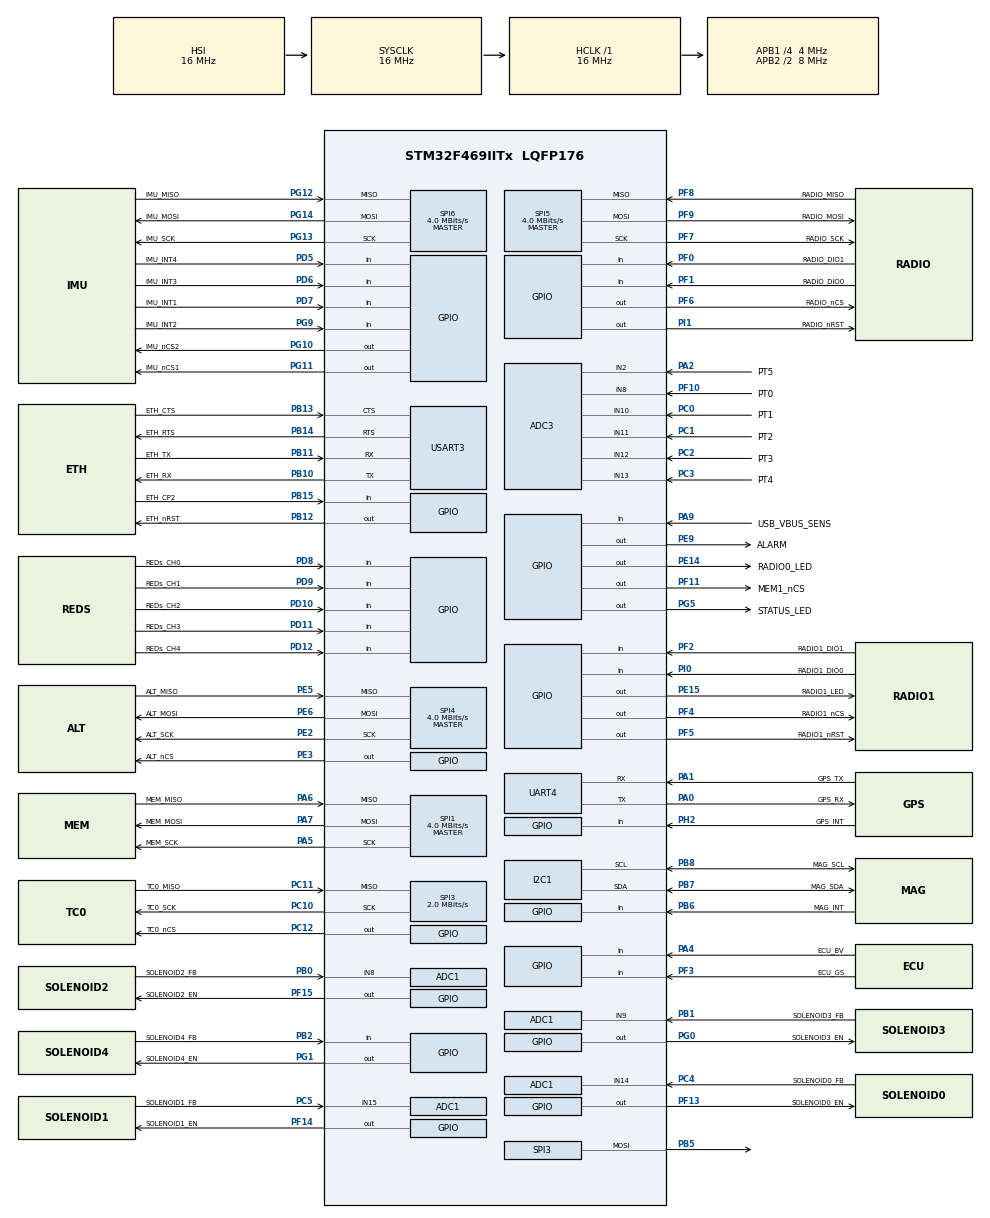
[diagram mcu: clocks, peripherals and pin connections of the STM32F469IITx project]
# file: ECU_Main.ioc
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ADC1.Channel-0\#ChannelRegularConversion=ADC_CHANNEL_8
ADC1.ClockPrescaler=ADC_CLOCK_SYNC_PCLK_DIV4
ADC1.NbrOfConversionFlag=1
ADC1.Rank-0\#ChannelRegularConversion=1
ADC1.SamplingTime-0\#ChannelRegularConversion=ADC_SAMPLETIME_3CYCLES
ADC1.master=1
ADC3.Channel-0\#ChannelRegularConversion=ADC_CHANNEL_10
ADC3.ClockPrescaler=ADC_CLOCK_SYNC_PCLK_DIV4
ADC3.NbrOfConversionFlag=1
ADC3.Rank-0\#ChannelRegularConversion=1
ADC3.SamplingTime-0\#ChannelRegularConversion=ADC_SAMPLETIME_3CYCLES
Mcu.Family=STM32F4
Mcu.Name=STM32F469IITx
Mcu.Package=LQFP176
NVIC.PriorityGroup=NVIC_PRIORITYGROUP_4
PA0/WKUP.GPIO_Label=GPS_RX
PA0/WKUP.Mode=Asynchronous
PA0/WKUP.Signal=UART4_TX
PA1.GPIO_Label=GPS_TX
PA1.Mode=Asynchronous
PA1.Signal=UART4_RX
PA11.GPIO_Label=USB_DM
PA11.Signal=USB_OTG_FS_DM
PA12.GPIO_Label=USB_DP
PA12.Signal=USB_OTG_FS_DP
PA13.Mode=JTAG_4_pins
PA13.Signal=SYS_JTMS-SWDIO
PA14.Mode=JTAG_4_pins
PA14.Signal=SYS_JTCK-SWCLK
PA15.Mode=JTAG_4_pins
PA15.Signal=SYS_JTDI
PA2.GPIO_Label=PT5
PA2.Signal=ADCx_IN2
PA4.GPIO_Label=ECU_BV
PA4.Signal=GPIO_Input
PA5.GPIO_Label=MEM_SCK
PA5.Mode=Full_Duplex_Master
PA5.Signal=SPI1_SCK
PA6.GPIO_Label=MEM_MISO
PA6.Mode=Full_Duplex_Master
PA6.Signal=SPI1_MISO
PA7.GPIO_Label=MEM_MOSI
PA7.Mode=Full_Duplex_Master
PA7.Signal=SPI1_MOSI
PA9.GPIO_Label=USB_VBUS_SENS
PA9.Signal=GPIO_Input
PB0.GPIO_Label=SOLENOID2_FB
PB0.Signal=ADCx_IN8
PB1.GPIO_Label=SOLENOID3_FB
PB1.Signal=ADCx_IN9
PB10.GPIO_Label=ETH_RX
PB10.Mode=Asynchronous
PB10.Signal=USART3_TX
PB11.GPIO_Label=ETH_TX
PB11.Mode=Asynchronous
PB11.Signal=USART3_RX
PB12.GPIO_Label=ETH_nRST
PB12.Signal=GPIO_Output
PB13.GPIO_Label=ETH_CTS
PB13.Mode=CTS_RTS
PB13.Signal=USART3_CTS
PB14.GPIO_Label=ETH_RTS
PB14.Mode=CTS_RTS
PB14.Signal=USART3_RTS
PB15.GPIO_Label=ETH_CP2
PB15.Signal=GPIO_Input
PB2/BOOT1.GPIO_Label=SOLENOID4_FB
PB2/BOOT1.Signal=GPIO_Input
PB3.Mode=JTAG_4_pins
PB3.Signal=SYS_JTDO-SWO
PB5.Mode=Full_Duplex_Master
PB5.Signal=SPI3_MOSI
PB6.GPIO_Label=MAG_INT
PB6.Signal=GPIO_Input
PB7.GPIO_Label=MAG_SDA
PB7.Mode=I2C
PB7.Signal=I2C1_SDA
PB8.GPIO_Label=MAG_SCL
PB8.Mode=I2C
PB8.Signal=I2C1_SCL
PC0.GPIO_Label=PT1
PC0.Signal=ADCx_IN10
PC1.GPIO_Label=PT2
PC1.Signal=ADCx_IN11
PC10.GPIO_Label=TC0_SCK
PC10.Mode=Full_Duplex_Master
PC10.Signal=SPI3_SCK
PC11.GPIO_Label=TC0_MISO
PC11.Mode=Full_Duplex_Master
PC11.Signal=SPI3_MISO
PC12.GPIO_Label=TC0_nCS
PC12.Signal=GPIO_Output
PC2.GPIO_Label=PT3
PC2.Signal=ADCx_IN12
PC3.GPIO_Label=PT4
PC3.Signal=ADCx_IN13
PC4.GPIO_Label=SOLENOID0_FB
PC4.Signal=ADCx_IN14
PC5.GPIO_Label=SOLENOID1_FB
PC5.Signal=ADCx_IN15
PD10.GPIO_Label=REDs_CH2
PD10.Signal=GPIO_Input
PD11.GPIO_Label=REDs_CH3
PD11.Signal=GPIO_Input
PD12.GPIO_Label=REDs_CH4
PD12.Signal=GPIO_Input
PD5.GPIO_Label=IMU_INT4
PD5.Signal=GPIO_Input
PD6.GPIO_Label=IMU_INT3
PD6.Signal=GPIO_Input
PD7.GPIO_Label=IMU_INT1
PD7.Signal=GPIO_Input
PD8.GPIO_Label=REDs_CH0
PD8.Signal=GPIO_Input
PD9.GPIO_Label=REDs_CH1
PD9.Signal=GPIO_Input
PE14.GPIO_Label=RADIO0_LED
PE14.Signal=GPIO_Output
PE15.GPIO_Label=RADIO1_LED
PE15.Signal=GPIO_Output
PE2.GPIO_Label=ALT_SCK
PE2.Mode=Full_Duplex_Master
PE2.Signal=SPI4_SCK
PE3.GPIO_Label=ALT_nCS
PE3.Signal=GPIO_Output
PE5.GPIO_Label=ALT_MISO
PE5.Mode=Full_Duplex_Master
PE5.Signal=SPI4_MISO
PE6.GPIO_Label=ALT_MOSI
PE6.Mode=Full_Duplex_Master
PE6.Signal=SPI4_MOSI
PE9.GPIO_Label=ALARM
PE9.Signal=GPIO_Output
PF0.GPIO_Label=RADIO_DIO1
PF0.Signal=GPIO_Input
PF1.GPIO_Label=RADIO_DIO0
PF1.Signal=GPIO_Input
PF10.GPIO_Label=PT0
PF10.Mode=IN8
PF10.Signal=ADC3_IN8
PF11.GPIO_Label=MEM1_nCS
PF11.Signal=GPIO_Output
PF13.GPIO_Label=SOLENOID0_EN
PF13.Signal=GPIO_Output
PF14.GPIO_Label=SOLENOID1_EN
PF14.Signal=GPIO_Output
PF15.GPIO_Label=SOLENOID2_EN
PF15.Signal=GPIO_Output
PF2.GPIO_Label=RADIO1_DIO1
PF2.Signal=GPIO_Input
PF3.GPIO_Label=ECU_GS
PF3.Signal=GPIO_Input
PF4.GPIO_Label=RADIO1_nCS
PF4.Signal=GPIO_Output
PF5.GPIO_Label=RADIO1_nRST
PF5.Signal=GPIO_Output
PF6.GPIO_Label=RADIO_nCS
PF6.Signal=GPIO_Output
PF7.GPIO_Label=RADIO_SCK
PF7.Mode=Full_Duplex_Master
PF7.Signal=SPI5_SCK
PF8.GPIO_Label=RADIO_MISO
PF8.Mode=Full_Duplex_Master
PF8.Signal=SPI5_MISO
PF9.GPIO_Label=RADIO_MOSI
PF9.Mode=Full_Duplex_Master
PF9.Signal=SPI5_MOSI
PG0.GPIO_Label=SOLENOID3_EN
PG0.Signal=GPIO_Output
PG1.GPIO_Label=SOLENOID4_EN
PG1.Signal=GPIO_Output
PG10.GPIO_Label=IMU_nCS2
PG10.Signal=GPIO_Output
PG11.GPIO_Label=IMU_nCS1
PG11.Signal=GPIO_Output
PG12.GPIO_Label=IMU_MISO
PG12.Mode=Full_Duplex_Master
PG12.Signal=SPI6_MISO
PG13.GPIO_Label=IMU_SCK
PG13.Mode=Full_Duplex_Master
PG13.Signal=SPI6_SCK
PG14.GPIO_Label=IMU_MOSI
PG14.Mode=Full_Duplex_Master
PG14.Signal=SPI6_MOSI
PG5.GPIO_Label=STATUS_LED
PG5.Signal=GPIO_Output
PG9.GPIO_Label=IMU_INT2
PG9.Signal=GPIO_Input
PH2.GPIO_Label=GPS_INT
PH2.Signal=GPIO_Input
PI0.GPIO_Label=RADIO1_DIO0
PI0.Signal=GPIO_Input
PI1.GPIO_Label=RADIO_nRST
PI1.Signal=GPIO_Output
ProjectManager.HeapSize=0x200
ProjectManager.StackSize=0x400
ProjectManager.TargetToolchain=CMake
RCC.AHBFreq_Value=16000000
RCC.APB1CLKDivider=RCC_HCLK_DIV4
RCC.APB1Freq_Value=4000000
RCC.APB1TimFreq_Value=8000000
RCC.APB2CLKDivider=RCC_HCLK_DIV2
RCC.APB2Freq_Value=8000000
RCC.APB2TimFreq_Value=16000000
RCC.CortexFreq_Value=16000000
RCC.HCLKFreq_Value=16000000
RCC.HSE_VALUE=16000000
RCC.PLLM=8
RCC.PLLN=168
RCC.PLLQ=7
RCC.SYSCLKFreq_VALUE=16000000
RCC.USBFreq_Value=48000000
RCC.VCOOutputFreq_Value=336000000
SH.ADCx_IN10.0=ADC3_IN10,IN10
SH.ADCx_IN11.0=ADC3_IN11,IN11
SH.ADCx_IN12.0=ADC3_IN12,IN12
SH.ADCx_IN13.0=ADC3_IN13,IN13
SH.ADCx_IN14.0=ADC1_IN14,IN14
SH.ADCx_IN15.0=ADC1_IN15,IN15
SH.ADCx_IN2.0=ADC3_IN2,IN2
SH.ADCx_IN8.0=ADC1_IN8,IN8
SH.ADCx_IN9.0=ADC1_IN9,IN9
SPI1.CalculateBaudRate=4.0 MBits/s
SPI1.Direction=SPI_DIRECTION_2LINES
SPI1.Mode=SPI_MODE_MASTER
SPI1.VirtualType=VM_MASTER
SPI3.CalculateBaudRate=2.0 MBits/s
SPI3.Direction=SPI_DIRECTION_2LINES
SPI3.Mode=SPI_MODE_MASTER
SPI3.VirtualType=VM_MASTER
SPI4.CalculateBaudRate=4.0 MBits/s
SPI4.Direction=SPI_DIRECTION_2LINES
SPI4.Mode=SPI_MODE_MASTER
SPI4.VirtualType=VM_MASTER
SPI5.CalculateBaudRate=4.0 MBits/s
SPI5.Direction=SPI_DIRECTION_2LINES
SPI5.Mode=SPI_MODE_MASTER
SPI5.VirtualType=VM_MASTER
SPI6.CalculateBaudRate=4.0 MBits/s
SPI6.Direction=SPI_DIRECTION_2LINES
SPI6.Mode=SPI_MODE_MASTER
SPI6.VirtualType=VM_MASTER
TIM5.Prescaler=83
UART4.VirtualMode=Asynchronous
USART3.VirtualMode=VM_ASYNC
VP_TIM5_VS_ClockSourceINT.Mode=Internal
board=custom

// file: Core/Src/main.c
/* USER CODE BEGIN Header */
/**
  ******************************************************************************
  * @file           : main.c
  * @brief          : Main program body
  ******************************************************************************
  * @attention
  *
  * Copyright (c) 2026 STMicroelectronics.
  * All rights reserved.
  *
  * This software is licensed under terms that can be found in the LICENSE file
  * in the root directory of this software component.
  * If no LICENSE file comes with this software, it is provided AS-IS.
  *
  ******************************************************************************
  */
/* USER CODE END Header */
#include "main.h"

/* USER CODE BEGIN Includes */
#include "cpp_main.h"
/* USER CODE END Includes */

ADC_HandleTypeDef hadc1;
ADC_HandleTypeDef hadc3;

I2C_HandleTypeDef hi2c1;

SPI_HandleTypeDef hspi1;
SPI_HandleTypeDef hspi3;
SPI_HandleTypeDef hspi4;
SPI_HandleTypeDef hspi5;
SPI_HandleTypeDef hspi6;

TIM_HandleTypeDef htim5;

UART_HandleTypeDef huart4;
UART_HandleTypeDef huart3;

void SystemClock_Config(void);
static void MX_GPIO_Init(void);
static void MX_I2C1_Init(void);
static void MX_SPI1_Init(void);
static void MX_SPI3_Init(void);
static void MX_SPI4_Init(void);
static void MX_SPI5_Init(void);
static void MX_SPI6_Init(void);
static void MX_UART4_Init(void);
static void MX_USART3_UART_Init(void);
static void MX_TIM5_Init(void);
static void MX_ADC1_Init(void);
static void MX_ADC3_Init(void);

int main(void)
{

  /* MCU Configuration--------------------------------------------------------*/

  /* Reset of all peripherals, Initializes the Flash interface and the Systick. */
  HAL_Init();

  /* Configure the system clock */
  SystemClock_Config();

  /* Initialize all configured peripherals */
  MX_GPIO_Init();
  MX_I2C1_Init();
  MX_SPI1_Init();
  MX_SPI3_Init();
  MX_SPI4_Init();
  MX_SPI5_Init();
  MX_SPI6_Init();
  MX_UART4_Init();
  MX_USART3_UART_Init();
  MX_TIM5_Init();
  MX_ADC1_Init();
  MX_ADC3_Init();
  /* USER CODE BEGIN 2 */
  cpp_main();

  /* USER CODE END 2 */

  /* Infinite loop */
  while (1)
  {

  }
}

void SystemClock_Config(void)
{
  RCC_OscInitTypeDef RCC_OscInitStruct = {0};
  RCC_ClkInitTypeDef RCC_ClkInitStruct = {0};

  /** Configure the main internal regulator output voltage
  */
  __HAL_RCC_PWR_CLK_ENABLE();
  __HAL_PWR_VOLTAGESCALING_CONFIG(PWR_REGULATOR_VOLTAGE_SCALE3);

  /** Initializes the RCC Oscillators according to the specified parameters
  * in the RCC_OscInitTypeDef structure.
  */
  RCC_OscInitStruct.OscillatorType = RCC_OSCILLATORTYPE_HSI;
  RCC_OscInitStruct.HSIState = RCC_HSI_ON;
  RCC_OscInitStruct.HSICalibrationValue = RCC_HSICALIBRATION_DEFAULT;
  RCC_OscInitStruct.PLL.PLLState = RCC_PLL_NONE;
  if (HAL_RCC_OscConfig(&RCC_OscInitStruct) != HAL_OK)
  {
    Error_Handler();
  }

  /** Initializes the CPU, AHB and APB buses clocks
  */
  RCC_ClkInitStruct.ClockType = RCC_CLOCKTYPE_HCLK|RCC_CLOCKTYPE_SYSCLK
                              |RCC_CLOCKTYPE_PCLK1|RCC_CLOCKTYPE_PCLK2;
  RCC_ClkInitStruct.SYSCLKSource = RCC_SYSCLKSOURCE_HSI;
  RCC_ClkInitStruct.AHBCLKDivider = RCC_SYSCLK_DIV1;
  RCC_ClkInitStruct.APB1CLKDivider = RCC_HCLK_DIV4;
  RCC_ClkInitStruct.APB2CLKDivider = RCC_HCLK_DIV2;

  if (HAL_RCC_ClockConfig(&RCC_ClkInitStruct, FLASH_LATENCY_0) != HAL_OK)
  {
    Error_Handler();
  }
}

static void MX_ADC1_Init(void)
{

  ADC_ChannelConfTypeDef sConfig = {0};

  /** Configure the global features of the ADC (Clock, Resolution, Data Alignment and number of conversion)
  */
  hadc1.Instance = ADC1;
  hadc1.Init.ClockPrescaler = ADC_CLOCK_SYNC_PCLK_DIV4;
  hadc1.Init.Resolution = ADC_RESOLUTION_12B;
  hadc1.Init.ScanConvMode = DISABLE;
  hadc1.Init.ContinuousConvMode = DISABLE;
  hadc1.Init.DiscontinuousConvMode = DISABLE;
  hadc1.Init.ExternalTrigConvEdge = ADC_EXTERNALTRIGCONVEDGE_NONE;
  hadc1.Init.ExternalTrigConv = ADC_SOFTWARE_START;
  hadc1.Init.DataAlign = ADC_DATAALIGN_RIGHT;
  hadc1.Init.NbrOfConversion = 1;
  hadc1.Init.DMAContinuousRequests = DISABLE;
  hadc1.Init.EOCSelection = ADC_EOC_SINGLE_CONV;
  if (HAL_ADC_Init(&hadc1) != HAL_OK)
  {
    Error_Handler();
  }

  /** Configure for the selected ADC regular channel its corresponding rank in the sequencer and its sample time.
  */
  sConfig.Channel = ADC_CHANNEL_8;
  sConfig.Rank = 1;
  sConfig.SamplingTime = ADC_SAMPLETIME_3CYCLES;
  if (HAL_ADC_ConfigChannel(&hadc1, &sConfig) != HAL_OK)
  {
    Error_Handler();
  }

}

static void MX_ADC3_Init(void)
{

  ADC_ChannelConfTypeDef sConfig = {0};

  /** Configure the global features of the ADC (Clock, Resolution, Data Alignment and number of conversion)
  */
  hadc3.Instance = ADC3;
  hadc3.Init.ClockPrescaler = ADC_CLOCK_SYNC_PCLK_DIV4;
  hadc3.Init.Resolution = ADC_RESOLUTION_12B;
  hadc3.Init.ScanConvMode = DISABLE;
  hadc3.Init.ContinuousConvMode = DISABLE;
  hadc3.Init.DiscontinuousConvMode = DISABLE;
  hadc3.Init.ExternalTrigConvEdge = ADC_EXTERNALTRIGCONVEDGE_NONE;
  hadc3.Init.ExternalTrigConv = ADC_SOFTWARE_START;
  hadc3.Init.DataAlign = ADC_DATAALIGN_RIGHT;
  hadc3.Init.NbrOfConversion = 1;
  hadc3.Init.DMAContinuousRequests = DISABLE;
  hadc3.Init.EOCSelection = ADC_EOC_SINGLE_CONV;
  if (HAL_ADC_Init(&hadc3) != HAL_OK)
  {
    Error_Handler();
  }

  /** Configure for the selected ADC regular channel its corresponding rank in the sequencer and its sample time.
  */
  sConfig.Channel = ADC_CHANNEL_10;
  sConfig.Rank = 1;
  sConfig.SamplingTime = ADC_SAMPLETIME_3CYCLES;
  if (HAL_ADC_ConfigChannel(&hadc3, &sConfig) != HAL_OK)
  {
    Error_Handler();
  }

}

static void MX_I2C1_Init(void)
{

  hi2c1.Instance = I2C1;
  hi2c1.Init.ClockSpeed = 100000;
  hi2c1.Init.DutyCycle = I2C_DUTYCYCLE_2;
  hi2c1.Init.OwnAddress1 = 0;
  hi2c1.Init.AddressingMode = I2C_ADDRESSINGMODE_7BIT;
  hi2c1.Init.DualAddressMode = I2C_DUALADDRESS_DISABLE;
  hi2c1.Init.OwnAddress2 = 0;
  hi2c1.Init.GeneralCallMode = I2C_GENERALCALL_DISABLE;
  hi2c1.Init.NoStretchMode = I2C_NOSTRETCH_DISABLE;
  if (HAL_I2C_Init(&hi2c1) != HAL_OK)
  {
    Error_Handler();
  }

}

static void MX_SPI1_Init(void)
{

  /* SPI1 parameter configuration*/
  hspi1.Instance = SPI1;
  hspi1.Init.Mode = SPI_MODE_MASTER;
  hspi1.Init.Direction = SPI_DIRECTION_2LINES;
  hspi1.Init.DataSize = SPI_DATASIZE_8BIT;
  hspi1.Init.CLKPolarity = SPI_POLARITY_LOW;
  hspi1.Init.CLKPhase = SPI_PHASE_1EDGE;
  hspi1.Init.NSS = SPI_NSS_SOFT;
  hspi1.Init.BaudRatePrescaler = SPI_BAUDRATEPRESCALER_2;
  hspi1.Init.FirstBit = SPI_FIRSTBIT_MSB;
  hspi1.Init.TIMode = SPI_TIMODE_DISABLE;
  hspi1.Init.CRCCalculation = SPI_CRCCALCULATION_DISABLE;
  hspi1.Init.CRCPolynomial = 10;
  if (HAL_SPI_Init(&hspi1) != HAL_OK)
  {
    Error_Handler();
  }

}

static void MX_SPI3_Init(void)
{

  /* SPI3 parameter configuration*/
  hspi3.Instance = SPI3;
  hspi3.Init.Mode = SPI_MODE_MASTER;
  hspi3.Init.Direction = SPI_DIRECTION_2LINES;
  hspi3.Init.DataSize = SPI_DATASIZE_8BIT;
  hspi3.Init.CLKPolarity = SPI_POLARITY_LOW;
  hspi3.Init.CLKPhase = SPI_PHASE_1EDGE;
  hspi3.Init.NSS = SPI_NSS_SOFT;
  hspi3.Init.BaudRatePrescaler = SPI_BAUDRATEPRESCALER_2;
  hspi3.Init.FirstBit = SPI_FIRSTBIT_MSB;
  hspi3.Init.TIMode = SPI_TIMODE_DISABLE;
  hspi3.Init.CRCCalculation = SPI_CRCCALCULATION_DISABLE;
  hspi3.Init.CRCPolynomial = 10;
  if (HAL_SPI_Init(&hspi3) != HAL_OK)
  {
    Error_Handler();
  }

}

static void MX_SPI4_Init(void)
{

  /* SPI4 parameter configuration*/
  hspi4.Instance = SPI4;
  hspi4.Init.Mode = SPI_MODE_MASTER;
  hspi4.Init.Direction = SPI_DIRECTION_2LINES;
  hspi4.Init.DataSize = SPI_DATASIZE_8BIT;
  hspi4.Init.CLKPolarity = SPI_POLARITY_LOW;
  hspi4.Init.CLKPhase = SPI_PHASE_1EDGE;
  hspi4.Init.NSS = SPI_NSS_SOFT;
  hspi4.Init.BaudRatePrescaler = SPI_BAUDRATEPRESCALER_2;
  hspi4.Init.FirstBit = SPI_FIRSTBIT_MSB;
  hspi4.Init.TIMode = SPI_TIMODE_DISABLE;
  hspi4.Init.CRCCalculation = SPI_CRCCALCULATION_DISABLE;
  hspi4.Init.CRCPolynomial = 10;
  if (HAL_SPI_Init(&hspi4) != HAL_OK)
  {
    Error_Handler();
  }

}

static void MX_SPI5_Init(void)
{

  /* SPI5 parameter configuration*/
  hspi5.Instance = SPI5;
  hspi5.Init.Mode = SPI_MODE_MASTER;
  hspi5.Init.Direction = SPI_DIRECTION_2LINES;
  hspi5.Init.DataSize = SPI_DATASIZE_8BIT;
  hspi5.Init.CLKPolarity = SPI_POLARITY_LOW;
  hspi5.Init.CLKPhase = SPI_PHASE_1EDGE;
  hspi5.Init.NSS = SPI_NSS_SOFT;
  hspi5.Init.BaudRatePrescaler = SPI_BAUDRATEPRESCALER_2;
  hspi5.Init.FirstBit = SPI_FIRSTBIT_MSB;
  hspi5.Init.TIMode = SPI_TIMODE_DISABLE;
  hspi5.Init.CRCCalculation = SPI_CRCCALCULATION_DISABLE;
  hspi5.Init.CRCPolynomial = 10;
  if (HAL_SPI_Init(&hspi5) != HAL_OK)
  {
    Error_Handler();
  }

}

static void MX_SPI6_Init(void)
{

  /* SPI6 parameter configuration*/
  hspi6.Instance = SPI6;
  hspi6.Init.Mode = SPI_MODE_MASTER;
  hspi6.Init.Direction = SPI_DIRECTION_2LINES;
  hspi6.Init.DataSize = SPI_DATASIZE_8BIT;
  hspi6.Init.CLKPolarity = SPI_POLARITY_LOW;
  hspi6.Init.CLKPhase = SPI_PHASE_1EDGE;
  hspi6.Init.NSS = SPI_NSS_SOFT;
  hspi6.Init.BaudRatePrescaler = SPI_BAUDRATEPRESCALER_2;
  hspi6.Init.FirstBit = SPI_FIRSTBIT_MSB;
  hspi6.Init.TIMode = SPI_TIMODE_DISABLE;
  hspi6.Init.CRCCalculation = SPI_CRCCALCULATION_DISABLE;
  hspi6.Init.CRCPolynomial = 10;
  if (HAL_SPI_Init(&hspi6) != HAL_OK)
  {
    Error_Handler();
  }

}

static void MX_TIM5_Init(void)
{

  TIM_ClockConfigTypeDef sClockSourceConfig = {0};
  TIM_MasterConfigTypeDef sMasterConfig = {0};

  htim5.Instance = TIM5;
  htim5.Init.Prescaler = 83;
  htim5.Init.CounterMode = TIM_COUNTERMODE_UP;
  htim5.Init.Period = 4294967295;
  htim5.Init.ClockDivision = TIM_CLOCKDIVISION_DIV1;
  htim5.Init.AutoReloadPreload = TIM_AUTORELOAD_PRELOAD_DISABLE;
  if (HAL_TIM_Base_Init(&htim5) != HAL_OK)
  {
    Error_Handler();
  }
  sClockSourceConfig.ClockSource = TIM_CLOCKSOURCE_INTERNAL;
  if (HAL_TIM_ConfigClockSource(&htim5, &sClockSourceConfig) != HAL_OK)
  {
    Error_Handler();
  }
  sMasterConfig.MasterOutputTrigger = TIM_TRGO_RESET;
  sMasterConfig.MasterSlaveMode = TIM_MASTERSLAVEMODE_DISABLE;
  if (HAL_TIMEx_MasterConfigSynchronization(&htim5, &sMasterConfig) != HAL_OK)
  {
    Error_Handler();
  }

}

static void MX_UART4_Init(void)
{

  huart4.Instance = UART4;
  huart4.Init.BaudRate = 115200;
  huart4.Init.WordLength = UART_WORDLENGTH_8B;
  huart4.Init.StopBits = UART_STOPBITS_1;
  huart4.Init.Parity = UART_PARITY_NONE;
  huart4.Init.Mode = UART_MODE_TX_RX;
  huart4.Init.HwFlowCtl = UART_HWCONTROL_NONE;
  huart4.Init.OverSampling = UART_OVERSAMPLING_16;
  if (HAL_UART_Init(&huart4) != HAL_OK)
  {
    Error_Handler();
  }

}

static void MX_USART3_UART_Init(void)
{

  huart3.Instance = USART3;
  huart3.Init.BaudRate = 9600;
  huart3.Init.WordLength = UART_WORDLENGTH_8B;
  huart3.Init.StopBits = UART_STOPBITS_1;
  huart3.Init.Parity = UART_PARITY_NONE;
  huart3.Init.Mode = UART_MODE_TX_RX;
  huart3.Init.HwFlowCtl = UART_HWCONTROL_RTS_CTS;
  huart3.Init.OverSampling = UART_OVERSAMPLING_16;
  if (HAL_UART_Init(&huart3) != HAL_OK)
  {
    Error_Handler();
  }

}

static void MX_GPIO_Init(void)
{
  GPIO_InitTypeDef GPIO_InitStruct = {0};

  /* GPIO Ports Clock Enable */
  __HAL_RCC_GPIOE_CLK_ENABLE();
  __HAL_RCC_GPIOF_CLK_ENABLE();
  __HAL_RCC_GPIOC_CLK_ENABLE();
  __HAL_RCC_GPIOA_CLK_ENABLE();
  __HAL_RCC_GPIOH_CLK_ENABLE();
  __HAL_RCC_GPIOB_CLK_ENABLE();
  __HAL_RCC_GPIOG_CLK_ENABLE();
  __HAL_RCC_GPIOD_CLK_ENABLE();
  __HAL_RCC_GPIOI_CLK_ENABLE();

  /*Configure GPIO pin Output Level */
  HAL_GPIO_WritePin(GPIOE, ALT_nCS_Pin|ALARM_Pin|RADIO0_LED_Pin|RADIO1_LED_Pin, GPIO_PIN_RESET);

  /*Configure GPIO pin Output Level */
  HAL_GPIO_WritePin(GPIOF, RADIO1_nCS_Pin|RADIO1_nRST_Pin|RADIO_nCS_Pin|MEM1_nCS_Pin
                          |SOLENOID0_EN_Pin|SOLENOID1_EN_Pin|SOLENOID2_EN_Pin, GPIO_PIN_RESET);

  /*Configure GPIO pin Output Level */
  HAL_GPIO_WritePin(GPIOG, SOLENOID3_EN_Pin|SOLENOID4_EN_Pin|STATUS_LED_Pin|IMU_nCS2_Pin
                          |IMU_nCS1_Pin, GPIO_PIN_RESET);

  /*Configure GPIO pin Output Level */
  HAL_GPIO_WritePin(ETH_nRST_GPIO_Port, ETH_nRST_Pin, GPIO_PIN_RESET);

  /*Configure GPIO pin Output Level */
  HAL_GPIO_WritePin(RADIO_nRST_GPIO_Port, RADIO_nRST_Pin, GPIO_PIN_RESET);

  /*Configure GPIO pin Output Level */
  HAL_GPIO_WritePin(TC0_nCS_GPIO_Port, TC0_nCS_Pin, GPIO_PIN_RESET);

  /*Configure GPIO pins : ALT_nCS_Pin ALARM_Pin RADIO0_LED_Pin RADIO1_LED_Pin */
  GPIO_InitStruct.Pin = ALT_nCS_Pin|ALARM_Pin|RADIO0_LED_Pin|RADIO1_LED_Pin;
  GPIO_InitStruct.Mode = GPIO_MODE_OUTPUT_PP;
  GPIO_InitStruct.Pull = GPIO_NOPULL;
  GPIO_InitStruct.Speed = GPIO_SPEED_FREQ_LOW;
  HAL_GPIO_Init(GPIOE, &GPIO_InitStruct);

  /*Configure GPIO pins : RADIO_DIO1_Pin RADIO_DIO0_Pin RADIO1_DIO1_Pin ECU_GS_Pin */
  GPIO_InitStruct.Pin = RADIO_DIO1_Pin|RADIO_DIO0_Pin|RADIO1_DIO1_Pin|ECU_GS_Pin;
  GPIO_InitStruct.Mode = GPIO_MODE_INPUT;
  GPIO_InitStruct.Pull = GPIO_NOPULL;
  HAL_GPIO_Init(GPIOF, &GPIO_InitStruct);

  /*Configure GPIO pins : RADIO1_nCS_Pin RADIO1_nRST_Pin RADIO_nCS_Pin MEM1_nCS_Pin
                           SOLENOID0_EN_Pin SOLENOID1_EN_Pin SOLENOID2_EN_Pin */
  GPIO_InitStruct.Pin = RADIO1_nCS_Pin|RADIO1_nRST_Pin|RADIO_nCS_Pin|MEM1_nCS_Pin
                          |SOLENOID0_EN_Pin|SOLENOID1_EN_Pin|SOLENOID2_EN_Pin;
  GPIO_InitStruct.Mode = GPIO_MODE_OUTPUT_PP;
  GPIO_InitStruct.Pull = GPIO_NOPULL;
  GPIO_InitStruct.Speed = GPIO_SPEED_FREQ_LOW;
  HAL_GPIO_Init(GPIOF, &GPIO_InitStruct);

  /*Configure GPIO pin : GPS_INT_Pin */
  GPIO_InitStruct.Pin = GPS_INT_Pin;
  GPIO_InitStruct.Mode = GPIO_MODE_INPUT;
  GPIO_InitStruct.Pull = GPIO_NOPULL;
  HAL_GPIO_Init(GPS_INT_GPIO_Port, &GPIO_InitStruct);

  /*Configure GPIO pins : ECU_BV_Pin USB_VBUS_SENS_Pin */
  GPIO_InitStruct.Pin = ECU_BV_Pin|USB_VBUS_SENS_Pin;
  GPIO_InitStruct.Mode = GPIO_MODE_INPUT;
  GPIO_InitStruct.Pull = GPIO_NOPULL;
  HAL_GPIO_Init(GPIOA, &GPIO_InitStruct);

  /*Configure GPIO pins : SOLENOID4_FB_Pin ETH_CP2_Pin MAG_INT_Pin */
  GPIO_InitStruct.Pin = SOLENOID4_FB_Pin|ETH_CP2_Pin|MAG_INT_Pin;
  GPIO_InitStruct.Mode = GPIO_MODE_INPUT;
  GPIO_InitStruct.Pull = GPIO_NOPULL;
  HAL_GPIO_Init(GPIOB, &GPIO_InitStruct);

  /*Configure GPIO pins : SOLENOID3_EN_Pin SOLENOID4_EN_Pin STATUS_LED_Pin IMU_nCS2_Pin
                           IMU_nCS1_Pin */
  GPIO_InitStruct.Pin = SOLENOID3_EN_Pin|SOLENOID4_EN_Pin|STATUS_LED_Pin|IMU_nCS2_Pin
                          |IMU_nCS1_Pin;
  GPIO_InitStruct.Mode = GPIO_MODE_OUTPUT_PP;
  GPIO_InitStruct.Pull = GPIO_NOPULL;
  GPIO_InitStruct.Speed = GPIO_SPEED_FREQ_LOW;
  HAL_GPIO_Init(GPIOG, &GPIO_InitStruct);

  /*Configure GPIO pin : ETH_nRST_Pin */
  GPIO_InitStruct.Pin = ETH_nRST_Pin;
  GPIO_InitStruct.Mode = GPIO_MODE_OUTPUT_PP;
  GPIO_InitStruct.Pull = GPIO_NOPULL;
  GPIO_InitStruct.Speed = GPIO_SPEED_FREQ_LOW;
  HAL_GPIO_Init(ETH_nRST_GPIO_Port, &GPIO_InitStruct);

  /*Configure GPIO pins : REDs_CH0_Pin REDs_CH1_Pin REDs_CH2_Pin REDs_CH3_Pin
                           REDs_CH4_Pin IMU_INT4_Pin IMU_INT3_Pin IMU_INT1_Pin */
  GPIO_InitStruct.Pin = REDs_CH0_Pin|REDs_CH1_Pin|REDs_CH2_Pin|REDs_CH3_Pin
                          |REDs_CH4_Pin|IMU_INT4_Pin|IMU_INT3_Pin|IMU_INT1_Pin;
  GPIO_InitStruct.Mode = GPIO_MODE_INPUT;
  GPIO_InitStruct.Pull = GPIO_NOPULL;
  HAL_GPIO_Init(GPIOD, &GPIO_InitStruct);

  /*Configure GPIO pins : USB_DM_Pin USB_DP_Pin */
  GPIO_InitStruct.Pin = USB_DM_Pin|USB_DP_Pin;
  GPIO_InitStruct.Mode = GPIO_MODE_AF_PP;
  GPIO_InitStruct.Pull = GPIO_NOPULL;
  GPIO_InitStruct.Speed = GPIO_SPEED_FREQ_VERY_HIGH;
  GPIO_InitStruct.Alternate = GPIO_AF10_OTG_FS;
  HAL_GPIO_Init(GPIOA, &GPIO_InitStruct);

  /*Configure GPIO pin : RADIO1_DIO0_Pin */
  GPIO_InitStruct.Pin = RADIO1_DIO0_Pin;
  GPIO_InitStruct.Mode = GPIO_MODE_INPUT;
  GPIO_InitStruct.Pull = GPIO_NOPULL;
  HAL_GPIO_Init(RADIO1_DIO0_GPIO_Port, &GPIO_InitStruct);

  /*Configure GPIO pin : RADIO_nRST_Pin */
  GPIO_InitStruct.Pin = RADIO_nRST_Pin;
  GPIO_InitStruct.Mode = GPIO_MODE_OUTPUT_PP;
  GPIO_InitStruct.Pull = GPIO_NOPULL;
  GPIO_InitStruct.Speed = GPIO_SPEED_FREQ_LOW;
  HAL_GPIO_Init(RADIO_nRST_GPIO_Port, &GPIO_InitStruct);

  /*Configure GPIO pin : TC0_nCS_Pin */
  GPIO_InitStruct.Pin = TC0_nCS_Pin;
  GPIO_InitStruct.Mode = GPIO_MODE_OUTPUT_PP;
  GPIO_InitStruct.Pull = GPIO_NOPULL;
  GPIO_InitStruct.Speed = GPIO_SPEED_FREQ_LOW;
  HAL_GPIO_Init(TC0_nCS_GPIO_Port, &GPIO_InitStruct);

  /*Configure GPIO pin : IMU_INT2_Pin */
  GPIO_InitStruct.Pin = IMU_INT2_Pin;
  GPIO_InitStruct.Mode = GPIO_MODE_INPUT;
  GPIO_InitStruct.Pull = GPIO_NOPULL;
  HAL_GPIO_Init(IMU_INT2_GPIO_Port, &GPIO_InitStruct);

}

void Error_Handler(void)
{
  __disable_irq();
  while (1)
  {
  }
}
